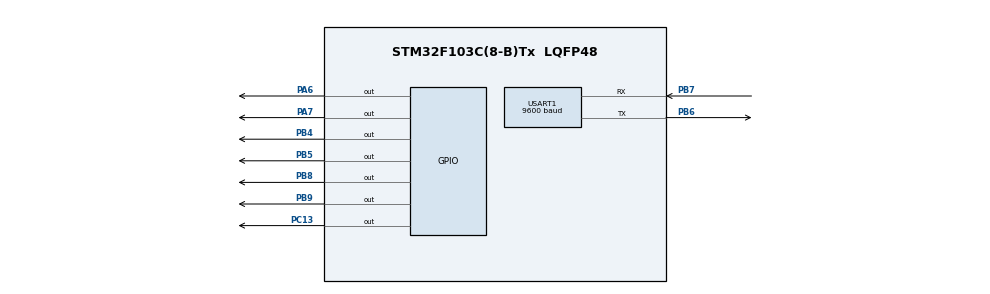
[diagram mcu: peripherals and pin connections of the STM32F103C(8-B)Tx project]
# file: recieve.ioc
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Mcu.Family=STM32F1
Mcu.Name=STM32F103C(8-B)Tx
Mcu.Package=LQFP48
NVIC.PriorityGroup=NVIC_PRIORITYGROUP_4
PA6.Signal=GPIO_Output
PA7.Signal=GPIO_Output
PB4.Signal=GPIO_Output
PB5.Signal=GPIO_Output
PB6.Mode=Asynchronous
PB6.Signal=USART1_TX
PB7.Mode=Asynchronous
PB7.Signal=USART1_RX
PB8.Signal=GPIO_Output
PB9.Signal=GPIO_Output
PC13-TAMPER-RTC.Signal=GPIO_Output
PD0-OSC_IN.Mode=HSE-External-Oscillator
PD0-OSC_IN.Signal=RCC_OSC_IN
PD1-OSC_OUT.Mode=HSE-External-Oscillator
PD1-OSC_OUT.Signal=RCC_OSC_OUT
ProjectManager.HeapSize=0x200
ProjectManager.StackSize=0x400
ProjectManager.TargetToolchain=STM32CubeIDE
RCC.APB1Freq_Value=8000000
RCC.APB2Freq_Value=8000000
USART1.BaudRate=9600
USART1.VirtualMode=VM_ASYNC
board=custom

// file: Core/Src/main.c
/* USER CODE BEGIN Header */
/**
  ******************************************************************************
  * @file           : main.c
  * @brief          : Main program body
  ******************************************************************************
  * @attention
  *
  * Copyright (c) 2024 STMicroelectronics.
  * All rights reserved.
  *
  * This software is licensed under terms that can be found in the LICENSE file
  * in the root directory of this software component.
  * If no LICENSE file comes with this software, it is provided AS-IS.
  *
  ******************************************************************************
  */
/* USER CODE END Header */
#include "main.h"

/* USER CODE BEGIN Includes */
uint8_t receivedData[1];
/* USER CODE END Includes */

UART_HandleTypeDef huart1;

void SystemClock_Config(void);
static void MX_GPIO_Init(void);
static void MX_USART1_UART_Init(void);

int main(void)
{

  /* MCU Configuration--------------------------------------------------------*/

  /* Reset of all peripherals, Initializes the Flash interface and the Systick. */
  HAL_Init();

  /* Configure the system clock */
  SystemClock_Config();

  /* Initialize all configured peripherals */
  MX_GPIO_Init();
  MX_USART1_UART_Init();
  /* USER CODE BEGIN 2 */
//  HAL_GPIO_WritePin(GPIOA, GPIO_PIN_6, GPIO_PIN_SET);
//  HAL_GPIO_WritePin(GPIOA, GPIO_PIN_7, GPIO_PIN_SET);
  /* USER CODE END 2 */

  /* Infinite loop */
  while (1)
  {
	    HAL_UART_Receive(&huart1, receivedData, 1, 100);

	    if (receivedData[0] == 1)//staight ahead
			{
	    	      HAL_GPIO_WritePin(GPIOC, GPIO_PIN_13, GPIO_PIN_RESET);

	    	      HAL_GPIO_WritePin(GPIOB, GPIO_PIN_4, GPIO_PIN_RESET);
	    	      HAL_GPIO_WritePin(GPIOB, GPIO_PIN_5, GPIO_PIN_SET);
	    	      HAL_GPIO_WritePin(GPIOA, GPIO_PIN_6, GPIO_PIN_RESET);
	    	      HAL_GPIO_WritePin(GPIOA, GPIO_PIN_7, GPIO_PIN_SET);

			      receivedData[0] =0;
			}

	     if (receivedData[0] == 2)//turn the right
			{
	    	      HAL_GPIO_WritePin(GPIOC, GPIO_PIN_13, GPIO_PIN_SET);

	    	      HAL_GPIO_WritePin(GPIOB, GPIO_PIN_4, GPIO_PIN_RESET);
	    	      HAL_GPIO_WritePin(GPIOB, GPIO_PIN_5, GPIO_PIN_SET);
	    	      HAL_GPIO_WritePin(GPIOA, GPIO_PIN_6, GPIO_PIN_RESET);
	    	      HAL_GPIO_WritePin(GPIOA, GPIO_PIN_7, GPIO_PIN_RESET);

			      receivedData[0] =0;
			}

	     if (receivedData[0] == 3)//turn the left
			{
	              HAL_GPIO_WritePin(GPIOC, GPIO_PIN_13, GPIO_PIN_RESET);

	    	      HAL_GPIO_WritePin(GPIOB, GPIO_PIN_4, GPIO_PIN_RESET);
	    	      HAL_GPIO_WritePin(GPIOB, GPIO_PIN_5, GPIO_PIN_RESET);
	    	      HAL_GPIO_WritePin(GPIOA, GPIO_PIN_6, GPIO_PIN_RESET);
	    	      HAL_GPIO_WritePin(GPIOA, GPIO_PIN_7, GPIO_PIN_SET);

			      receivedData[0] =0;
			}

	     if (receivedData[0] == 4)//go back
			{
	    	      HAL_GPIO_WritePin(GPIOC, GPIO_PIN_13, GPIO_PIN_SET);

                HAL_GPIO_WritePin(GPIOB, GPIO_PIN_4, GPIO_PIN_SET);
	    	      HAL_GPIO_WritePin(GPIOB, GPIO_PIN_5, GPIO_PIN_RESET);
	    	      HAL_GPIO_WritePin(GPIOA, GPIO_PIN_6, GPIO_PIN_SET);
	    	      HAL_GPIO_WritePin(GPIOA, GPIO_PIN_7, GPIO_PIN_RESET);

			      receivedData[0] =0;
			}

	     if (receivedData[0] == 5)//stop
	    {
	    	 HAL_GPIO_WritePin(GPIOC, GPIO_PIN_13, GPIO_PIN_RESET);

              HAL_GPIO_WritePin(GPIOB, GPIO_PIN_4, GPIO_PIN_RESET);
    	      HAL_GPIO_WritePin(GPIOB, GPIO_PIN_5, GPIO_PIN_RESET);
    	      HAL_GPIO_WritePin(GPIOA, GPIO_PIN_6, GPIO_PIN_RESET);
    	      HAL_GPIO_WritePin(GPIOA, GPIO_PIN_7, GPIO_PIN_RESET);
    	      receivedData[0] =0;
	    }
  }
}

void SystemClock_Config(void)
{
  RCC_OscInitTypeDef RCC_OscInitStruct = {0};
  RCC_ClkInitTypeDef RCC_ClkInitStruct = {0};

  /** Initializes the RCC Oscillators according to the specified parameters
  * in the RCC_OscInitTypeDef structure.
  */
  RCC_OscInitStruct.OscillatorType = RCC_OSCILLATORTYPE_HSI;
  RCC_OscInitStruct.HSIState = RCC_HSI_ON;
  RCC_OscInitStruct.HSICalibrationValue = RCC_HSICALIBRATION_DEFAULT;
  RCC_OscInitStruct.PLL.PLLState = RCC_PLL_NONE;
  if (HAL_RCC_OscConfig(&RCC_OscInitStruct) != HAL_OK)
  {
    Error_Handler();
  }

  /** Initializes the CPU, AHB and APB buses clocks
  */
  RCC_ClkInitStruct.ClockType = RCC_CLOCKTYPE_HCLK|RCC_CLOCKTYPE_SYSCLK
                              |RCC_CLOCKTYPE_PCLK1|RCC_CLOCKTYPE_PCLK2;
  RCC_ClkInitStruct.SYSCLKSource = RCC_SYSCLKSOURCE_HSI;
  RCC_ClkInitStruct.AHBCLKDivider = RCC_SYSCLK_DIV1;
  RCC_ClkInitStruct.APB1CLKDivider = RCC_HCLK_DIV1;
  RCC_ClkInitStruct.APB2CLKDivider = RCC_HCLK_DIV1;

  if (HAL_RCC_ClockConfig(&RCC_ClkInitStruct, FLASH_LATENCY_0) != HAL_OK)
  {
    Error_Handler();
  }
}

static void MX_USART1_UART_Init(void)
{

  huart1.Instance = USART1;
  huart1.Init.BaudRate = 9600;
  huart1.Init.WordLength = UART_WORDLENGTH_8B;
  huart1.Init.StopBits = UART_STOPBITS_1;
  huart1.Init.Parity = UART_PARITY_NONE;
  huart1.Init.Mode = UART_MODE_TX_RX;
  huart1.Init.HwFlowCtl = UART_HWCONTROL_NONE;
  huart1.Init.OverSampling = UART_OVERSAMPLING_16;
  if (HAL_UART_Init(&huart1) != HAL_OK)
  {
    Error_Handler();
  }

}

static void MX_GPIO_Init(void)
{
  GPIO_InitTypeDef GPIO_InitStruct = {0};

  /* GPIO Ports Clock Enable */
  __HAL_RCC_GPIOC_CLK_ENABLE();
  __HAL_RCC_GPIOD_CLK_ENABLE();
  __HAL_RCC_GPIOA_CLK_ENABLE();
  __HAL_RCC_GPIOB_CLK_ENABLE();

  /*Configure GPIO pin Output Level */
  HAL_GPIO_WritePin(GPIOC, GPIO_PIN_13, GPIO_PIN_RESET);

  /*Configure GPIO pin Output Level */
  HAL_GPIO_WritePin(GPIOA, GPIO_PIN_6|GPIO_PIN_7, GPIO_PIN_RESET);

  /*Configure GPIO pin Output Level */
  HAL_GPIO_WritePin(GPIOB, GPIO_PIN_4|GPIO_PIN_5|GPIO_PIN_8|GPIO_PIN_9, GPIO_PIN_RESET);

  /*Configure GPIO pin : PC13 */
  GPIO_InitStruct.Pin = GPIO_PIN_13;
  GPIO_InitStruct.Mode = GPIO_MODE_OUTPUT_PP;
  GPIO_InitStruct.Pull = GPIO_NOPULL;
  GPIO_InitStruct.Speed = GPIO_SPEED_FREQ_LOW;
  HAL_GPIO_Init(GPIOC, &GPIO_InitStruct);

  /*Configure GPIO pins : PA6 PA7 */
  GPIO_InitStruct.Pin = GPIO_PIN_6|GPIO_PIN_7;
  GPIO_InitStruct.Mode = GPIO_MODE_OUTPUT_PP;
  GPIO_InitStruct.Pull = GPIO_NOPULL;
  GPIO_InitStruct.Speed = GPIO_SPEED_FREQ_LOW;
  HAL_GPIO_Init(GPIOA, &GPIO_InitStruct);

  /*Configure GPIO pins : PB4 PB5 PB8 PB9 */
  GPIO_InitStruct.Pin = GPIO_PIN_4|GPIO_PIN_5|GPIO_PIN_8|GPIO_PIN_9;
  GPIO_InitStruct.Mode = GPIO_MODE_OUTPUT_PP;
  GPIO_InitStruct.Pull = GPIO_NOPULL;
  GPIO_InitStruct.Speed = GPIO_SPEED_FREQ_LOW;
  HAL_GPIO_Init(GPIOB, &GPIO_InitStruct);

}

void Error_Handler(void)
{
  __disable_irq();
  while (1)
  {
  }
}
